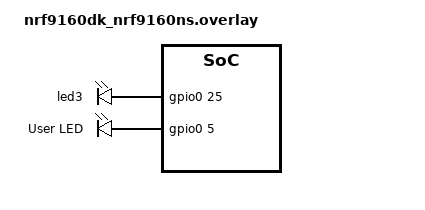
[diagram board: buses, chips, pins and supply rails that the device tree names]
/ {
	leds {
		led3: led_3 {
			//Changing led3 to use pin 25 instead of 5 (see https://github.com/nrfconnect/sdk-zephyr/blob/v2.6.0-rc1-ncs1/boards/arm/nrf9160dk_nrf9160/nrf9160dk_nrf9160_common.dts#L32)
			gpios = <&gpio0 25 ( GPIO_ACTIVE_HIGH)>;
		};
	};	
	simsels {
		compatible = "gpio-leds";
		simsel: mux_sim_sel {
			gpios = <&gpio0 5 GPIO_ACTIVE_HIGH>;
			label = "User LED";
		};
	};

	aliases {
		simsel = &simsel;
	};

};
